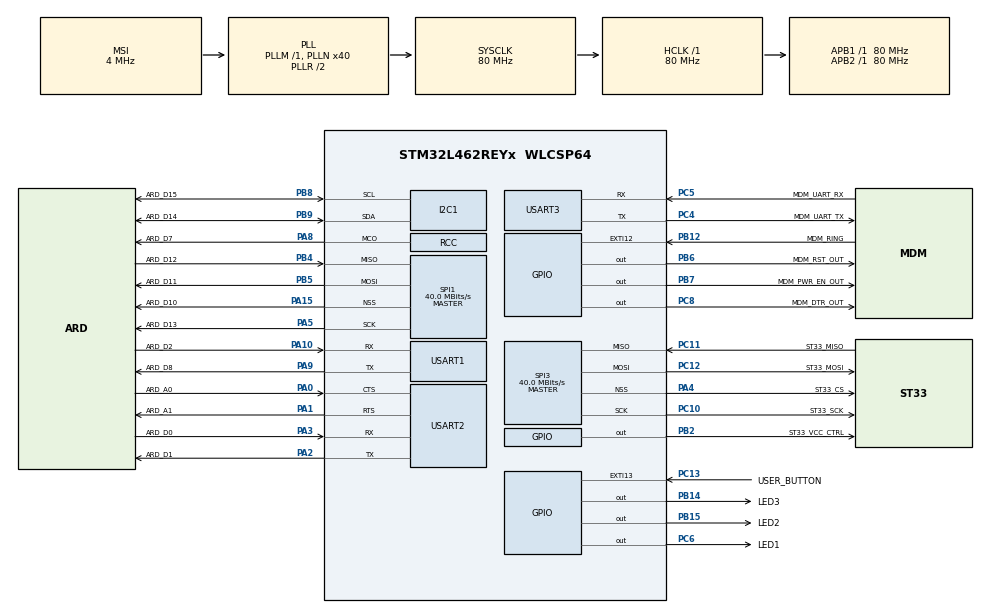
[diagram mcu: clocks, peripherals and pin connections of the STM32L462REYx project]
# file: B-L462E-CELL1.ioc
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Dma.Request0=USART1_RX
Dma.USART1_RX.0.Direction=DMA_PERIPH_TO_MEMORY
Dma.USART1_RX.0.Instance=DMA1_Channel5
Dma.USART1_RX.0.MemDataAlignment=DMA_MDATAALIGN_BYTE
Dma.USART1_RX.0.MemInc=DMA_MINC_ENABLE
Dma.USART1_RX.0.Mode=DMA_NORMAL
Dma.USART1_RX.0.PeriphDataAlignment=DMA_PDATAALIGN_BYTE
Dma.USART1_RX.0.PeriphInc=DMA_PINC_DISABLE
Dma.USART1_RX.0.Priority=DMA_PRIORITY_LOW
FREERTOS.INCLUDE_uxTaskGetStackHighWaterMark=1
FREERTOS.INCLUDE_vTaskDelayUntil=1
FREERTOS.Tasks01=defaultTask,0,128,StartDefaultTask,Default,NULL,Dynamic,NULL,NULL
FREERTOS.configTOTAL_HEAP_SIZE=18432
FREERTOS.configUSE_COUNTING_SEMAPHORES=1
FREERTOS.configUSE_TIMERS=1
I2C1.Timing=0x10909CEC
Mcu.Family=STM32L4
Mcu.Name=STM32L462REYx
Mcu.Package=WLCSP64
NVIC.DMA1_Channel5_IRQn=true\:5\:0\:false\:false\:true\:true\:false\:true\:true
NVIC.EXTI15_10_IRQn=true\:5\:0\:false\:false\:true\:true\:true\:true\:true
NVIC.PriorityGroup=NVIC_PRIORITYGROUP_4
NVIC.TIM1_UP_TIM16_IRQn=true\:0\:0\:false\:false\:true\:false\:false\:true\:true
NVIC.TimeBase=TIM1_UP_TIM16_IRQn
NVIC.TimeBaseIP=TIM1
NVIC.USART1_IRQn=true\:5\:0\:false\:false\:true\:true\:true\:true\:true
NVIC.USART2_IRQn=true\:5\:0\:false\:false\:true\:true\:true\:true\:true
NVIC.USART3_IRQn=true\:5\:0\:false\:false\:true\:true\:true\:true\:true
PA0.GPIO_Label=ARD_A0
PA0.Mode=CTS_RTS
PA0.Signal=USART2_CTS
PA1.GPIO_Label=ARD_A1
PA1.Mode=CTS_RTS
PA1.Signal=USART2_RTS
PA10.GPIO_Label=ARD_D2
PA10.Mode=Asynchronous
PA10.Signal=USART1_RX
PA13\ (JTMS/SWDIO).Mode=Serial_Wire
PA13\ (JTMS/SWDIO).Signal=SYS_JTMS-SWDIO
PA14\ (JTCK/SWCLK).Mode=Serial_Wire
PA14\ (JTCK/SWCLK).Signal=SYS_JTCK-SWCLK
PA15\ (JTDI).GPIO_Label=ARD_D10
PA15\ (JTDI).Mode=NSS_Signal_Hard_Output
PA15\ (JTDI).Signal=SPI1_NSS
PA2.GPIO_Label=ARD_D1
PA2.Mode=Asynchronous
PA2.Signal=USART2_TX
PA3.GPIO_Label=ARD_D0
PA3.Mode=Asynchronous
PA3.Signal=USART2_RX
PA4.GPIO_Label=ST33_CS
PA4.Mode=NSS_Signal_Hard_Output
PA4.Signal=SPI3_NSS
PA5.GPIO_Label=ARD_D13
PA5.Mode=Full_Duplex_Master
PA5.Signal=SPI1_SCK
PA6.Signal=QUADSPI_BK1_IO3
PA7.Signal=QUADSPI_BK1_IO2
PA8.GPIO_Label=ARD_D7
PA8.Mode=Clock-out
PA8.Signal=RCC_MCO
PA9.GPIO_Label=ARD_D8
PA9.Mode=Asynchronous
PA9.Signal=USART1_TX
PB0.Signal=QUADSPI_BK1_IO1
PB1.Signal=QUADSPI_BK1_IO0
PB10.Signal=QUADSPI_CLK
PB11.Signal=QUADSPI_BK1_NCS
PB12.GPIO_Label=MDM_RING
PB12.Signal=GPXTI12
PB13.GPIO_Label=MDM_UART_CTS
PB13.Signal=USART3_CTS
PB14.GPIO_Label=LED3
PB14.Signal=GPIO_Output
PB15.GPIO_Label=LED2
PB15.Signal=GPIO_Output
PB2.GPIO_Label=ST33_VCC_CTRL
PB2.Signal=GPIO_Output
PB4\ (NJTRST).GPIO_Label=ARD_D12
PB4\ (NJTRST).Mode=Full_Duplex_Master
PB4\ (NJTRST).Signal=SPI1_MISO
PB5.GPIO_Label=ARD_D11
PB5.Mode=Full_Duplex_Master
PB5.Signal=SPI1_MOSI
PB6.GPIO_Label=MDM_RST_OUT
PB6.Signal=GPIO_Output
PB7.GPIO_Label=MDM_PWR_EN_OUT
PB7.Signal=GPIO_Output
PB8.GPIO_Label=ARD_D15
PB8.Mode=I2C
PB8.Signal=I2C1_SCL
PB9.GPIO_Label=ARD_D14
PB9.Mode=I2C
PB9.Signal=I2C1_SDA
PC10.GPIO_Label=ST33_SCK
PC10.Mode=Full_Duplex_Master
PC10.Signal=SPI3_SCK
PC11.GPIO_Label=ST33_MISO
PC11.Mode=Full_Duplex_Master
PC11.Signal=SPI3_MISO
PC12.GPIO_Label=ST33_MOSI
PC12.Mode=Full_Duplex_Master
PC12.Signal=SPI3_MOSI
PC13.GPIO_Label=USER_BUTTON
PC13.Signal=GPXTI13
PC14-OSC32_IN\ (PC14).Mode=LSE-External-Oscillator
PC14-OSC32_IN\ (PC14).Signal=RCC_OSC32_IN
PC15-OSC32_OUT\ (PC15).Mode=LSE-External-Oscillator
PC15-OSC32_OUT\ (PC15).Signal=RCC_OSC32_OUT
PC4.GPIO_Label=MDM_UART_TX
PC4.Mode=Asynchronous
PC4.Signal=USART3_TX
PC5.GPIO_Label=MDM_UART_RX
PC5.Mode=Asynchronous
PC5.Signal=USART3_RX
PC6.GPIO_Label=LED1
PC6.Signal=GPIO_Output
PC8.GPIO_Label=MDM_DTR_OUT
PC8.Signal=GPIO_Output
PD2.GPIO_Label=MDM_UART_RTS
PD2.Signal=USART3_RTS
PH0-OSC_IN\ (PH0).Mode=HSE-External-Oscillator
PH0-OSC_IN\ (PH0).Signal=RCC_OSC_IN
PH1-OSC_OUT\ (PH1).Mode=HSE-External-Oscillator
PH1-OSC_OUT\ (PH1).Signal=RCC_OSC_OUT
ProjectManager.HeapSize=0x200
ProjectManager.StackSize=0x400
ProjectManager.TargetToolchain=STM32CubeIDE
RCC.ADCFreq_Value=48000000
RCC.AHBFreq_Value=80000000
RCC.APB1Freq_Value=80000000
RCC.APB1TimFreq_Value=80000000
RCC.APB2Freq_Value=80000000
RCC.APB2TimFreq_Value=80000000
RCC.CortexFreq_Value=80000000
RCC.HCLKFreq_Value=80000000
RCC.HSE_VALUE=8000000
RCC.HSI48_VALUE=48000000
RCC.HSI_VALUE=16000000
RCC.MSI_VALUE=4000000
RCC.PLLN=40
RCC.PLLSAI1N=24
RCC.RTCClockSelection=RCC_RTCCLKSOURCE_LSE
RCC.SYSCLKFreq_VALUE=80000000
RCC.SYSCLKSource=RCC_SYSCLKSOURCE_PLLCLK
RCC.USBFreq_Value=48000000
RCC.VCOOutputFreq_Value=160000000
SPI1.CalculateBaudRate=40.0 MBits/s
SPI1.Direction=SPI_DIRECTION_2LINES
SPI1.Mode=SPI_MODE_MASTER
SPI1.VirtualNSS=VM_NSSHARD
SPI1.VirtualType=VM_MASTER
SPI3.CalculateBaudRate=40.0 MBits/s
SPI3.Direction=SPI_DIRECTION_2LINES
SPI3.Mode=SPI_MODE_MASTER
SPI3.VirtualNSS=VM_NSSHARD
SPI3.VirtualType=VM_MASTER
USART1.VirtualMode-Asynchronous=VM_ASYNC
USART2.VirtualMode-Asynchronous=VM_ASYNC
USART3.VirtualMode-Asynchronous=VM_ASYNC
VP_AES_VS_AES.Mode=AES_Activate
VP_FREERTOS_VS_CMSIS_V1.Mode=CMSIS_V1
VP_RNG_VS_RNG.Mode=RNG_Activate
VP_RTC_VS_RTC_Activate.Mode=RTC_Enabled
VP_SYS_VS_tim1.Mode=TIM1
board=B-L462E-CELL1

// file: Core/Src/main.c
/* USER CODE BEGIN Header */
/**
  ******************************************************************************
  * @file           : main.c
  * @brief          : Main program body
  ******************************************************************************
  * @attention
  *
  * <h2><center>&copy; Copyright (c) 2021 STMicroelectronics.
  * All rights reserved.</center></h2>
  *
  * This software component is licensed by ST under Ultimate Liberty license
  * SLA0044, the "License"; You may not use this file except in compliance with
  * the License. You may obtain a copy of the License at:
  *                             www.st.com/SLA0044
  *
  ******************************************************************************
  */
/* USER CODE END Header */
#include "main.h"
#include "cmsis_os.h"
#include "aes.h"
#include "dma.h"
#include "i2c.h"
#include "rng.h"
#include "rtc.h"
#include "spi.h"
#include "usart.h"
#include "gpio.h"
#include "quadspi.h"
#include "flash_if.h"

/* USER CODE BEGIN Includes */

#include <mbedtls/ctr_drbg.h>
/* USER CODE END Includes */

/* USER CODE BEGIN PV */
UART_HandleTypeDef *const g_console_huart = &huart1;

#ifdef USE_AIBP
UART_HandleTypeDef *const g_ai_bridge_huart = &huart2;
#endif

//void mbedtls_ctr_drbg_free( mbedtls_ctr_drbg_context *ctx )
//{}
//void mbedtls_ctr_drbg_init( mbedtls_ctr_drbg_context *ctx ){}
//int mbedtls_ctr_drbg_random( void *p_rng, unsigned char *output,
//        size_t output_len )
//{
//
//	return 0;}
//int mbedtls_ctr_drbg_seed( mbedtls_ctr_drbg_context *ctx,
//                           int (*f_entropy)(void *, unsigned char *, size_t),
//                           void *p_entropy,
//                           const unsigned char *custom,
//                           size_t len )
//{return 0;}
/* USER CODE END PV */

void SystemClock_Config(void);
void MX_FREERTOS_Init(void);

int main(void)
{

  /* MCU Configuration--------------------------------------------------------*/

  /* Reset of all peripherals, Initializes the Flash interface and the Systick. */
  HAL_Init();

  /* Configure the system clock */
  SystemClock_Config();

  /* Initialize all configured peripherals */
  MX_GPIO_Init();
  MX_DMA_Init();
  MX_I2C1_Init();
  MX_RNG_Init();
  MX_RTC_Init();
  MX_SPI1_Init();
  MX_SPI3_Init();
  MX_USART1_UART_Init();
  MX_USART2_UART_Init();
  MX_AES_Init();
  MX_USART3_UART_Init();
  MX_QUADSPI_Init();
  /* USER CODE BEGIN 2 */
  FLASH_If_Init();
  /* USER CODE END 2 */

  /* Call init function for freertos objects (in freertos.c) */
  MX_FREERTOS_Init();
  /* Start scheduler */
  osKernelStart();

  /* We should never get here as control is now taken by the scheduler */
  /* Infinite loop */
  while (1)
  {

  }
}

void SystemClock_Config(void)
{
  RCC_OscInitTypeDef RCC_OscInitStruct = {0};
  RCC_ClkInitTypeDef RCC_ClkInitStruct = {0};
  RCC_PeriphCLKInitTypeDef PeriphClkInit = {0};

  /** Configure LSE Drive Capability
  */
  HAL_PWR_EnableBkUpAccess();
  __HAL_RCC_LSEDRIVE_CONFIG(RCC_LSEDRIVE_LOW);
  /** Initializes the RCC Oscillators according to the specified parameters
  * in the RCC_OscInitTypeDef structure.
  */
  RCC_OscInitStruct.OscillatorType = RCC_OSCILLATORTYPE_LSE|RCC_OSCILLATORTYPE_MSI;
  RCC_OscInitStruct.LSEState = RCC_LSE_ON;
  RCC_OscInitStruct.MSIState = RCC_MSI_ON;
  RCC_OscInitStruct.MSICalibrationValue = 0;
  RCC_OscInitStruct.MSIClockRange = RCC_MSIRANGE_6;
  RCC_OscInitStruct.PLL.PLLState = RCC_PLL_ON;
  RCC_OscInitStruct.PLL.PLLSource = RCC_PLLSOURCE_MSI;
  RCC_OscInitStruct.PLL.PLLM = 1;
  RCC_OscInitStruct.PLL.PLLN = 40;
  RCC_OscInitStruct.PLL.PLLP = RCC_PLLP_DIV7;
  RCC_OscInitStruct.PLL.PLLQ = RCC_PLLQ_DIV2;
  RCC_OscInitStruct.PLL.PLLR = RCC_PLLR_DIV2;
  if (HAL_RCC_OscConfig(&RCC_OscInitStruct) != HAL_OK)
  {
    Error_Handler();
  }
  /** Initializes the CPU, AHB and APB buses clocks
  */
  RCC_ClkInitStruct.ClockType = RCC_CLOCKTYPE_HCLK|RCC_CLOCKTYPE_SYSCLK
                              |RCC_CLOCKTYPE_PCLK1|RCC_CLOCKTYPE_PCLK2;
  RCC_ClkInitStruct.SYSCLKSource = RCC_SYSCLKSOURCE_PLLCLK;
  RCC_ClkInitStruct.AHBCLKDivider = RCC_SYSCLK_DIV1;
  RCC_ClkInitStruct.APB1CLKDivider = RCC_HCLK_DIV1;
  RCC_ClkInitStruct.APB2CLKDivider = RCC_HCLK_DIV1;

  if (HAL_RCC_ClockConfig(&RCC_ClkInitStruct, FLASH_LATENCY_4) != HAL_OK)
  {
    Error_Handler();
  }
  PeriphClkInit.PeriphClockSelection = RCC_PERIPHCLK_RTC|RCC_PERIPHCLK_USART1
                              |RCC_PERIPHCLK_USART2|RCC_PERIPHCLK_USART3
                              |RCC_PERIPHCLK_I2C1|RCC_PERIPHCLK_RNG;
  PeriphClkInit.Usart1ClockSelection = RCC_USART1CLKSOURCE_PCLK2;
  PeriphClkInit.Usart2ClockSelection = RCC_USART2CLKSOURCE_PCLK1;
  PeriphClkInit.Usart3ClockSelection = RCC_USART3CLKSOURCE_PCLK1;
  PeriphClkInit.I2c1ClockSelection = RCC_I2C1CLKSOURCE_PCLK1;
  PeriphClkInit.RTCClockSelection = RCC_RTCCLKSOURCE_LSE;
  PeriphClkInit.RngClockSelection = RCC_RNGCLKSOURCE_PLLSAI1;
  PeriphClkInit.PLLSAI1.PLLSAI1Source = RCC_PLLSOURCE_MSI;
  PeriphClkInit.PLLSAI1.PLLSAI1M = 1;
  PeriphClkInit.PLLSAI1.PLLSAI1N = 24;
  PeriphClkInit.PLLSAI1.PLLSAI1P = RCC_PLLP_DIV7;
  PeriphClkInit.PLLSAI1.PLLSAI1Q = RCC_PLLQ_DIV2;
  PeriphClkInit.PLLSAI1.PLLSAI1R = RCC_PLLR_DIV2;
  PeriphClkInit.PLLSAI1.PLLSAI1ClockOut = RCC_PLLSAI1_48M2CLK;
  if (HAL_RCCEx_PeriphCLKConfig(&PeriphClkInit) != HAL_OK)
  {
    Error_Handler();
  }
  HAL_RCC_MCOConfig(RCC_MCO1, RCC_MCO1SOURCE_SYSCLK, RCC_MCODIV_1);
  /** Configure the main internal regulator output voltage
  */
  if (HAL_PWREx_ControlVoltageScaling(PWR_REGULATOR_VOLTAGE_SCALE1) != HAL_OK)
  {
    Error_Handler();
  }
  /** Enable MSI Auto calibration
  */
  HAL_RCCEx_EnableMSIPLLMode();
}

 /**
  * @brief  Period elapsed callback in non blocking mode
  * @note   This function is called  when TIM1 interrupt took place, inside
  * HAL_TIM_IRQHandler(). It makes a direct call to HAL_IncTick() to increment
  * a global variable "uwTick" used as application time base.
  * @param  htim : TIM handle
  * @retval None
  */
void HAL_TIM_PeriodElapsedCallback(TIM_HandleTypeDef *htim)
{
  if (htim->Instance == TIM1) {
    HAL_IncTick();
  }
}

void Error_Handler(void)
{
  __disable_irq();
  while (1)
  {
  }
}

/************************ (C) COPYRIGHT STMicroelectronics *****END OF FILE****/

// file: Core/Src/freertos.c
/* USER CODE BEGIN Header */
/**
  ******************************************************************************
  * File Name          : freertos.c
  * Description        : Code for freertos applications
  ******************************************************************************
  * @attention
  *
  * <h2><center>&copy; Copyright (c) 2021 STMicroelectronics.
  * All rights reserved.</center></h2>
  *
  * This software component is licensed by ST under Ultimate Liberty license
  * SLA0044, the "License"; You may not use this file except in compliance with
  * the License. You may obtain a copy of the License at:
  *                             www.st.com/SLA0044
  *
  ******************************************************************************
  */
/* USER CODE END Header */

#include "FreeRTOS.h"
#include "task.h"
#include "main.h"
#include "cmsis_os.h"

/* USER CODE BEGIN Includes */
#include "application.h"

/* USER CODE END Includes */

osThreadId defaultTaskHandle;

void StartDefaultTask(void const * argument);

void MX_FREERTOS_Init(void); /* (MISRA C 2004 rule 8.1) */

/* GetIdleTaskMemory prototype (linked to static allocation support) */
void vApplicationGetIdleTaskMemory( StaticTask_t **ppxIdleTaskTCBBuffer, StackType_t **ppxIdleTaskStackBuffer, uint32_t *pulIdleTaskStackSize );

/* GetTimerTaskMemory prototype (linked to static allocation support) */
void vApplicationGetTimerTaskMemory( StaticTask_t **ppxTimerTaskTCBBuffer, StackType_t **ppxTimerTaskStackBuffer, uint32_t *pulTimerTaskStackSize );

/* USER CODE BEGIN GET_IDLE_TASK_MEMORY */
static StaticTask_t xIdleTaskTCBBuffer;
static StackType_t xIdleStack[configMINIMAL_STACK_SIZE];

void vApplicationGetIdleTaskMemory( StaticTask_t **ppxIdleTaskTCBBuffer, StackType_t **ppxIdleTaskStackBuffer, uint32_t *pulIdleTaskStackSize )
{
  *ppxIdleTaskTCBBuffer = &xIdleTaskTCBBuffer;
  *ppxIdleTaskStackBuffer = &xIdleStack[0];
  *pulIdleTaskStackSize = configMINIMAL_STACK_SIZE;
  /* place for user code */
}
/* USER CODE END GET_IDLE_TASK_MEMORY */

void vApplicationStackOverflowHook(TaskHandle_t xTask, signed char *pcTaskName)
{
  while (1) {}
}

/* USER CODE BEGIN GET_TIMER_TASK_MEMORY */
static StaticTask_t xTimerTaskTCBBuffer;
static StackType_t xTimerStack[configTIMER_TASK_STACK_DEPTH];

void vApplicationGetTimerTaskMemory( StaticTask_t **ppxTimerTaskTCBBuffer, StackType_t **ppxTimerTaskStackBuffer, uint32_t *pulTimerTaskStackSize )
{
  *ppxTimerTaskTCBBuffer = &xTimerTaskTCBBuffer;
  *ppxTimerTaskStackBuffer = &xTimerStack[0];
  *pulTimerTaskStackSize = configTIMER_TASK_STACK_DEPTH;
  /* place for user code */
}
/* USER CODE END GET_TIMER_TASK_MEMORY */

void MX_FREERTOS_Init(void) {
  /* USER CODE BEGIN Init */
  application_init();
  /* USER CODE END Init */

  /* Create the thread(s) */
  /* definition and creation of defaultTask */
  osThreadDef(defaultTask, StartDefaultTask, osPriorityNormal, 0, 128);
  defaultTaskHandle = osThreadCreate(osThread(defaultTask), NULL);

}

void StartDefaultTask(void const * argument)
{
  for(;;)
  {
    osDelay(1);
  }
}

/************************ (C) COPYRIGHT STMicroelectronics *****END OF FILE****/
